AUTOSAR XML (schema 00044)
package /E40_Platform_System_SystemPackage/Components
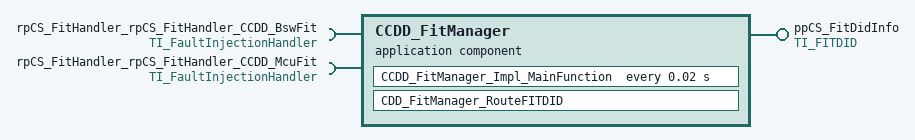
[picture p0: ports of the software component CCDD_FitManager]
  application sw component type CCDD_FitManager
    provide port ppCS_FitDidInfo: server-com-spec{operation=CDD_FitManager_RouteFITDID, queue-length=1}, provided-interface=TI_FITDID
    require port rpCS_FitHandler_rpCS_FitHandler_CCDD_BswFit: client-com-spec=FaultInjectionHandler, required-interface=TI_FaultInjectionHandler
    require port rpCS_FitHandler_rpCS_FitHandler_CCDD_McuFit: client-com-spec=FaultInjectionHandler, required-interface=TI_FaultInjectionHandler
    behavior IB_CCDD_FitManager
      operation invoked event OIE_ppCS_FitDidInfo_CDD_FitManager_RouteFITDIDTrigByCDD_FitManager_RouteFITDID: start-on-event=CDD_FitManager_RouteFITDID, operation=ppCS_FitDidInfo.CDD_FitManager_RouteFITDID
      timing event TECCDD_FitManager_Impl_MainFunction: start-on-event=CCDD_FitManager_Impl_MainFunction, period=0.02
      port-api-options:
        enable-take-address=false, indirect-api=false, port=ppCS_FitDidInfo
        enable-take-address=false, indirect-api=false, port=rpCS_FitHandler_rpCS_FitHandler_CCDD_BswFit
        enable-take-address=false, indirect-api=false, port=rpCS_FitHandler_rpCS_FitHandler_CCDD_McuFit
      runnable CDD_FitManager_RouteFITDID: can-be-invoked-concurrently=true
      runnable CCDD_FitManager_Impl_MainFunction: can-be-invoked-concurrently=true
        sync call OA_rpCS_FitHandler_rpCS_FitHandler_CCDD_BswFit_FaultInjectionHandler: operation=rpCS_FitHandler_rpCS_FitHandler_CCDD_BswFit.FaultInjectionHandler
        sync call OA_rpCS_FitHandler_rpCS_FitHandler_CCDD_McuFit_FaultInjectionHandler: operation=rpCS_FitHandler_rpCS_FitHandler_CCDD_McuFit.FaultInjectionHandler
  swc implementation IMPL_CCDD_FitManager: behavior=IB_CCDD_FitManager
